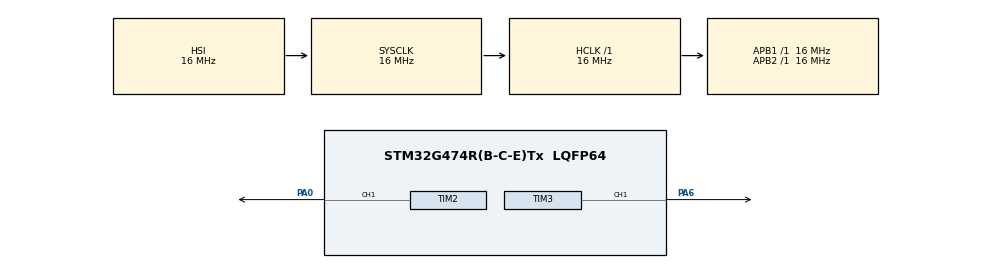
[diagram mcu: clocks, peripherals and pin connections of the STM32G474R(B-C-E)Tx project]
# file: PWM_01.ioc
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Mcu.Family=STM32G4
Mcu.Name=STM32G474R(B-C-E)Tx
Mcu.Package=LQFP64
NVIC.PriorityGroup=NVIC_PRIORITYGROUP_4
PA0.Signal=S_TIM2_CH1
PA6.Signal=S_TIM3_CH1
ProjectManager.HeapSize=0x200
ProjectManager.StackSize=0x400
ProjectManager.TargetToolchain=STM32CubeIDE
RCC.ADC12Freq_Value=16000000
RCC.ADC345Freq_Value=16000000
RCC.AHBFreq_Value=16000000
RCC.APB1Freq_Value=16000000
RCC.APB1TimFreq_Value=16000000
RCC.APB2Freq_Value=16000000
RCC.APB2TimFreq_Value=16000000
RCC.CortexFreq_Value=16000000
RCC.EXTERNAL_CLOCK_VALUE=12288000
RCC.HCLKFreq_Value=16000000
RCC.HSE_VALUE=24000000
RCC.HSI48_VALUE=48000000
RCC.HSI_VALUE=16000000
RCC.LSE_VALUE=32768
RCC.PLLM=RCC_PLLM_DIV4
RCC.PLLN=85
RCC.RTCClockSelection=RCC_RTCCLKSOURCE_LSE
RCC.SYSCLKFreq_VALUE=16000000
RCC.USBFreq_Value=170000000
RCC.VCOOutputFreq_Value=340000000
SH.S_TIM2_CH1.0=TIM2_CH1,PWM Generation1 CH1
SH.S_TIM3_CH1.0=TIM3_CH1,PWM Generation1 CH1
TIM2.AutoReloadPreload=TIM_AUTORELOAD_PRELOAD_ENABLE
TIM2.Channel-PWM\ Generation1\ CH1=TIM_CHANNEL_1
TIM2.PeriodNoDither=1000-1
TIM2.Prescaler=16-1
TIM2.PulseNoDither_1=750
TIM3.AutoReloadPreload=TIM_AUTORELOAD_PRELOAD_ENABLE
TIM3.Channel-PWM\ Generation1\ CH1=TIM_CHANNEL_1
TIM3.PeriodNoDither=1000-1
TIM3.Prescaler=16-1
TIM3.PulseNoDither_1=500
TIM4.PeriodNoDither=65535
TIM4.Prescaler=16-1
VP_SYS_VS_DBSignals.Mode=DisableDeadBatterySignals
VP_TIM2_VS_ClockSourceINT.Mode=Internal
VP_TIM3_VS_ClockSourceINT.Mode=Internal
VP_TIM4_VS_ClockSourceINT.Mode=Internal
board=NUCLEO-G474RE

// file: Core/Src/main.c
/* USER CODE BEGIN Header */
/**
  ******************************************************************************
  * @file           : main.c
  * @brief          : Main program body
  ******************************************************************************
  * @attention
  *
  * Copyright (c) 2026 STMicroelectronics.
  * All rights reserved.
  *
  * This software is licensed under terms that can be found in the LICENSE file
  * in the root directory of this software component.
  * If no LICENSE file comes with this software, it is provided AS-IS.
  *
  ******************************************************************************
	Hardware: NUCLEO-G474RE
	Objetivo: Gerar sinal PWM no CH1 do TIM2.

	Notas:

		Clock APB: 16 MHz
			Alvo de 1 kHz: O objetivo é que o timer incremente seu contador exatamente 1000 de vezes por segundo.

		Prescaler (PSC): f_CNT = f_TIM_CLK/(PSC+1)
			Para transformar 16 MHz em 1 MHz, dividimos por 16.
			Valor no registrador do PSC: 16−1

		Agora, cada "passo" (tick) do timer dura exatamente 1μs.

		Para atingir o alvo, dado que temos 1MHz, temos que definir o valor do counter_period como: 1M/1k = 1000 (1000-1).

		Então o timer vai contar até 1000 a um passo de 1us, logo ele vai estourar a cada 0.1ms.
  */
/* USER CODE END Header */
#include "main.h"

/* USER CODE BEGIN Includes */
uint32_t duty_cycle_01 = 100;
uint32_t duty_cycle_02 = 900;
/* USER CODE END Includes */

TIM_HandleTypeDef htim2;
TIM_HandleTypeDef htim3;
TIM_HandleTypeDef htim4;

void SystemClock_Config(void);
static void MX_GPIO_Init(void);
static void MX_TIM2_Init(void);
static void MX_TIM3_Init(void);
static void MX_TIM4_Init(void);

/* USER CODE BEGIN 0 */
void atraso_us (uint16_t us){
	__HAL_TIM_SET_COUNTER(&htim4, 0); // zerando o contador

	while( __HAL_TIM_GET_COUNTER(&htim4) <= us);
}
/* USER CODE END 0 */

int main(void)
{

  /* MCU Configuration--------------------------------------------------------*/

  /* Reset of all peripherals, Initializes the Flash interface and the Systick. */
  HAL_Init();

  /* Configure the system clock */
  SystemClock_Config();

  /* Initialize all configured peripherals */
  MX_GPIO_Init();
  MX_TIM2_Init();
  MX_TIM3_Init();
  MX_TIM4_Init();
  /* USER CODE BEGIN 2 */

  // Iniciando o timer do contador
  HAL_TIM_Base_Start(&htim4);
  HAL_Delay(200);

  // Iniciando os PWMs
  HAL_TIM_PWM_Start(&htim2, TIM_CHANNEL_1);
  atraso_us(500); // deslocamento da inicialização do timer
  HAL_TIM_PWM_Start(&htim3, TIM_CHANNEL_1);

  /* USER CODE END 2 */

  /* Infinite loop */
  while (1)
  {

    /* USER CODE BEGIN 3 */
	  __HAL_TIM_SET_COMPARE(&htim2, TIM_CHANNEL_1, duty_cycle_01);
	  __HAL_TIM_SET_COMPARE(&htim3, TIM_CHANNEL_1, duty_cycle_01);

	  duty_cycle_01 += 10;
	  if (duty_cycle_01 >= 900){duty_cycle_01 = 100;}

//	  __HAL_TIM_SET_COMPARE(&htim3, TIM_CHANNEL_1, duty_cycle_02);
//	  duty_cycle_02 -= 10;
//	  if (duty_cycle_02  < 100){duty_cycle_02 = 1000;}
//
	  HAL_Delay(200);
  }
  /* USER CODE END 3 */
}

void SystemClock_Config(void)
{
  RCC_OscInitTypeDef RCC_OscInitStruct = {0};
  RCC_ClkInitTypeDef RCC_ClkInitStruct = {0};

  /** Configure the main internal regulator output voltage
  */
  HAL_PWREx_ControlVoltageScaling(PWR_REGULATOR_VOLTAGE_SCALE1);

  /** Initializes the RCC Oscillators according to the specified parameters
  * in the RCC_OscInitTypeDef structure.
  */
  RCC_OscInitStruct.OscillatorType = RCC_OSCILLATORTYPE_HSI;
  RCC_OscInitStruct.HSIState = RCC_HSI_ON;
  RCC_OscInitStruct.HSICalibrationValue = RCC_HSICALIBRATION_DEFAULT;
  RCC_OscInitStruct.PLL.PLLState = RCC_PLL_NONE;
  if (HAL_RCC_OscConfig(&RCC_OscInitStruct) != HAL_OK)
  {
    Error_Handler();
  }

  /** Initializes the CPU, AHB and APB buses clocks
  */
  RCC_ClkInitStruct.ClockType = RCC_CLOCKTYPE_HCLK|RCC_CLOCKTYPE_SYSCLK
                              |RCC_CLOCKTYPE_PCLK1|RCC_CLOCKTYPE_PCLK2;
  RCC_ClkInitStruct.SYSCLKSource = RCC_SYSCLKSOURCE_HSI;
  RCC_ClkInitStruct.AHBCLKDivider = RCC_SYSCLK_DIV1;
  RCC_ClkInitStruct.APB1CLKDivider = RCC_HCLK_DIV1;
  RCC_ClkInitStruct.APB2CLKDivider = RCC_HCLK_DIV1;

  if (HAL_RCC_ClockConfig(&RCC_ClkInitStruct, FLASH_LATENCY_0) != HAL_OK)
  {
    Error_Handler();
  }
}

static void MX_TIM2_Init(void)
{

  TIM_ClockConfigTypeDef sClockSourceConfig = {0};
  TIM_MasterConfigTypeDef sMasterConfig = {0};
  TIM_OC_InitTypeDef sConfigOC = {0};

  htim2.Instance = TIM2;
  htim2.Init.Prescaler = 16-1;
  htim2.Init.CounterMode = TIM_COUNTERMODE_UP;
  htim2.Init.Period = 999;
  htim2.Init.ClockDivision = TIM_CLOCKDIVISION_DIV1;
  htim2.Init.AutoReloadPreload = TIM_AUTORELOAD_PRELOAD_ENABLE;
  if (HAL_TIM_Base_Init(&htim2) != HAL_OK)
  {
    Error_Handler();
  }
  sClockSourceConfig.ClockSource = TIM_CLOCKSOURCE_INTERNAL;
  if (HAL_TIM_ConfigClockSource(&htim2, &sClockSourceConfig) != HAL_OK)
  {
    Error_Handler();
  }
  if (HAL_TIM_PWM_Init(&htim2) != HAL_OK)
  {
    Error_Handler();
  }
  sMasterConfig.MasterOutputTrigger = TIM_TRGO_RESET;
  sMasterConfig.MasterSlaveMode = TIM_MASTERSLAVEMODE_DISABLE;
  if (HAL_TIMEx_MasterConfigSynchronization(&htim2, &sMasterConfig) != HAL_OK)
  {
    Error_Handler();
  }
  sConfigOC.OCMode = TIM_OCMODE_PWM1;
  sConfigOC.Pulse = 750;
  sConfigOC.OCPolarity = TIM_OCPOLARITY_HIGH;
  sConfigOC.OCFastMode = TIM_OCFAST_DISABLE;
  if (HAL_TIM_PWM_ConfigChannel(&htim2, &sConfigOC, TIM_CHANNEL_1) != HAL_OK)
  {
    Error_Handler();
  }
  HAL_TIM_MspPostInit(&htim2);

}

static void MX_TIM3_Init(void)
{

  TIM_ClockConfigTypeDef sClockSourceConfig = {0};
  TIM_MasterConfigTypeDef sMasterConfig = {0};
  TIM_OC_InitTypeDef sConfigOC = {0};

  htim3.Instance = TIM3;
  htim3.Init.Prescaler = 16-1;
  htim3.Init.CounterMode = TIM_COUNTERMODE_UP;
  htim3.Init.Period = 999;
  htim3.Init.ClockDivision = TIM_CLOCKDIVISION_DIV1;
  htim3.Init.AutoReloadPreload = TIM_AUTORELOAD_PRELOAD_ENABLE;
  if (HAL_TIM_Base_Init(&htim3) != HAL_OK)
  {
    Error_Handler();
  }
  sClockSourceConfig.ClockSource = TIM_CLOCKSOURCE_INTERNAL;
  if (HAL_TIM_ConfigClockSource(&htim3, &sClockSourceConfig) != HAL_OK)
  {
    Error_Handler();
  }
  if (HAL_TIM_PWM_Init(&htim3) != HAL_OK)
  {
    Error_Handler();
  }
  sMasterConfig.MasterOutputTrigger = TIM_TRGO_RESET;
  sMasterConfig.MasterSlaveMode = TIM_MASTERSLAVEMODE_DISABLE;
  if (HAL_TIMEx_MasterConfigSynchronization(&htim3, &sMasterConfig) != HAL_OK)
  {
    Error_Handler();
  }
  sConfigOC.OCMode = TIM_OCMODE_PWM1;
  sConfigOC.Pulse = 500;
  sConfigOC.OCPolarity = TIM_OCPOLARITY_HIGH;
  sConfigOC.OCFastMode = TIM_OCFAST_DISABLE;
  if (HAL_TIM_PWM_ConfigChannel(&htim3, &sConfigOC, TIM_CHANNEL_1) != HAL_OK)
  {
    Error_Handler();
  }
  HAL_TIM_MspPostInit(&htim3);

}

static void MX_TIM4_Init(void)
{

  TIM_ClockConfigTypeDef sClockSourceConfig = {0};
  TIM_MasterConfigTypeDef sMasterConfig = {0};

  htim4.Instance = TIM4;
  htim4.Init.Prescaler = 16-1;
  htim4.Init.CounterMode = TIM_COUNTERMODE_UP;
  htim4.Init.Period = 65535;
  htim4.Init.ClockDivision = TIM_CLOCKDIVISION_DIV1;
  htim4.Init.AutoReloadPreload = TIM_AUTORELOAD_PRELOAD_DISABLE;
  if (HAL_TIM_Base_Init(&htim4) != HAL_OK)
  {
    Error_Handler();
  }
  sClockSourceConfig.ClockSource = TIM_CLOCKSOURCE_INTERNAL;
  if (HAL_TIM_ConfigClockSource(&htim4, &sClockSourceConfig) != HAL_OK)
  {
    Error_Handler();
  }
  sMasterConfig.MasterOutputTrigger = TIM_TRGO_RESET;
  sMasterConfig.MasterSlaveMode = TIM_MASTERSLAVEMODE_DISABLE;
  if (HAL_TIMEx_MasterConfigSynchronization(&htim4, &sMasterConfig) != HAL_OK)
  {
    Error_Handler();
  }

}

static void MX_GPIO_Init(void)
{

  /* GPIO Ports Clock Enable */
  __HAL_RCC_GPIOA_CLK_ENABLE();

}

void Error_Handler(void)
{
  __disable_irq();
  while (1)
  {
  }
}
